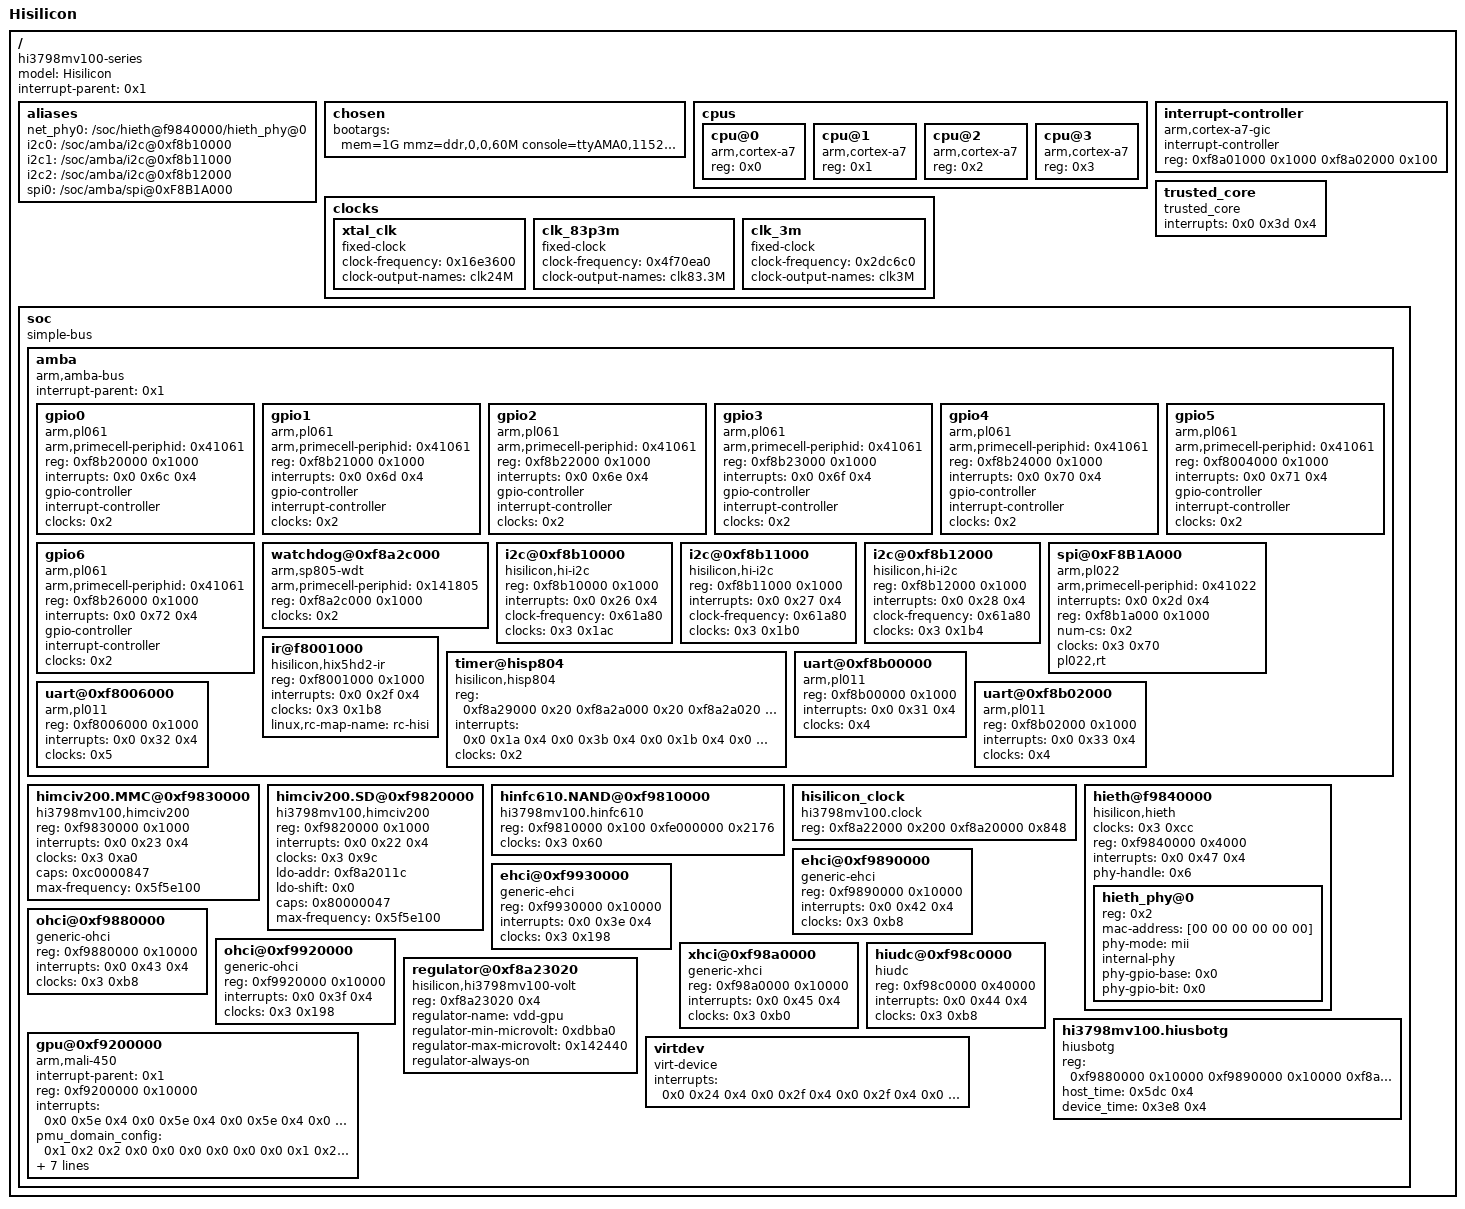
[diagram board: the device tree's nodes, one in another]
/dts-v1/;
// Decompiled from DTB appended to hi_kernel.bin at offset 0xA59D50
// DTB version: 17, size: 8935 bytes

/ {
	model = "Hisilicon";
	compatible = "hi3798mv100-series";
	#address-cells = <0x1>;
	#size-cells = <0x1>;
	interrupt-parent = <0x1>;
	aliases {
		net_phy0 = "/soc/hieth@f9840000/hieth_phy@0";
		i2c0 = "/soc/amba/i2c@0xf8b10000";
		i2c1 = "/soc/amba/i2c@0xf8b11000";
		i2c2 = "/soc/amba/i2c@0xf8b12000";
		spi0 = "/soc/amba/spi@0xF8B1A000";
	};
	chosen {
		bootargs = "mem=1G mmz=ddr,0,0,60M console=ttyAMA0,115200 root=/dev/mmcblk0p9 rootfstype=ext4 rootwait blkdevparts=mmcblk0:1M(boot),1M(bootargs),4M(baseparam),4M(pqparam),4M(logo),20M(kernel),64M(busybox),512M(backup),-(ubuntu)";
	};
	cpus {
		#address-cells = <0x1>;
		#size-cells = <0x0>;
		cpu@0 {
			device_type = "cpu";
			compatible = "arm,cortex-a7";
			reg = <0x0>;
		};
		cpu@1 {
			device_type = "cpu";
			compatible = "arm,cortex-a7";
			reg = <0x1>;
		};
		cpu@2 {
			device_type = "cpu";
			compatible = "arm,cortex-a7";
			reg = <0x2>;
		};
		cpu@3 {
			device_type = "cpu";
			compatible = "arm,cortex-a7";
			reg = <0x3>;
		};
	};
	clocks {
		xtal_clk {
			compatible = "fixed-clock";
			#clock-cells = <0x0>;
			clock-frequency = <0x16e3600>;
			clock-output-names = "clk24M";
			linux,phandle = <0x2>;
			phandle = <0x2>;
		};
		clk_83p3m {
			compatible = "fixed-clock";
			#clock-cells = <0x0>;
			clock-frequency = <0x4f70ea0>;
			clock-output-names = "clk83.3M";
			linux,phandle = <0x4>;
			phandle = <0x4>;
		};
		clk_3m {
			compatible = "fixed-clock";
			#clock-cells = <0x0>;
			clock-frequency = <0x2dc6c0>;
			clock-output-names = "clk3M";
			linux,phandle = <0x5>;
			phandle = <0x5>;
		};
	};
	interrupt-controller {
		compatible = "arm,cortex-a7-gic";
		#interrupt-cells = <0x3>;
		#address-cells = <0x0>;
		interrupt-controller;
		reg = <0xf8a01000 0x1000 0xf8a02000 0x100>;
		linux,phandle = <0x1>;
		phandle = <0x1>;
	};
	trusted_core {
		compatible = "trusted_core";
		interrupts = <0x0 0x3d 0x4>;
	};
	soc {
		#address-cells = <0x1>;
		#size-cells = <0x1>;
		compatible = "simple-bus";
		device_type = "soc";
		ranges = <0x0 0x0 0xffffffff>;
		amba {
			compatible = "arm,amba-bus";
			#address-cells = <0x1>;
			#size-cells = <0x1>;
			interrupt-parent = <0x1>;
			ranges;
			gpio0 {
				compatible = "arm,pl061", "arm,primecell";
				arm,primecell-periphid = <0x41061>;
				reg = <0xf8b20000 0x1000>;
				interrupts = <0x0 0x6c 0x4>;
				gpio-controller;
				#gpio-cells = <0x2>;
				interrupt-controller;
				#interrupt-cells = <0x2>;
				clocks = <0x2>;
				clock-names = "apb_pclk";
			};
			gpio1 {
				compatible = "arm,pl061", "arm,primecell";
				arm,primecell-periphid = <0x41061>;
				reg = <0xf8b21000 0x1000>;
				interrupts = <0x0 0x6d 0x4>;
				gpio-controller;
				#gpio-cells = <0x2>;
				interrupt-controller;
				#interrupt-cells = <0x2>;
				clocks = <0x2>;
				clock-names = "apb_pclk";
			};
			gpio2 {
				compatible = "arm,pl061", "arm,primecell";
				arm,primecell-periphid = <0x41061>;
				reg = <0xf8b22000 0x1000>;
				interrupts = <0x0 0x6e 0x4>;
				gpio-controller;
				#gpio-cells = <0x2>;
				interrupt-controller;
				#interrupt-cells = <0x2>;
				clocks = <0x2>;
				clock-names = "apb_pclk";
			};
			gpio3 {
				compatible = "arm,pl061", "arm,primecell";
				arm,primecell-periphid = <0x41061>;
				reg = <0xf8b23000 0x1000>;
				interrupts = <0x0 0x6f 0x4>;
				gpio-controller;
				#gpio-cells = <0x2>;
				interrupt-controller;
				#interrupt-cells = <0x2>;
				clocks = <0x2>;
				clock-names = "apb_pclk";
			};
			gpio4 {
				compatible = "arm,pl061", "arm,primecell";
				arm,primecell-periphid = <0x41061>;
				reg = <0xf8b24000 0x1000>;
				interrupts = <0x0 0x70 0x4>;
				gpio-controller;
				#gpio-cells = <0x2>;
				interrupt-controller;
				#interrupt-cells = <0x2>;
				clocks = <0x2>;
				clock-names = "apb_pclk";
			};
			gpio5 {
				compatible = "arm,pl061", "arm,primecell";
				arm,primecell-periphid = <0x41061>;
				reg = <0xf8004000 0x1000>;
				interrupts = <0x0 0x71 0x4>;
				gpio-controller;
				#gpio-cells = <0x2>;
				interrupt-controller;
				#interrupt-cells = <0x2>;
				clocks = <0x2>;
				clock-names = "apb_pclk";
			};
			gpio6 {
				compatible = "arm,pl061", "arm,primecell";
				arm,primecell-periphid = <0x41061>;
				reg = <0xf8b26000 0x1000>;
				interrupts = <0x0 0x72 0x4>;
				gpio-controller;
				#gpio-cells = <0x2>;
				interrupt-controller;
				#interrupt-cells = <0x2>;
				clocks = <0x2>;
				clock-names = "apb_pclk";
			};
			watchdog@0xf8a2c000 {
				compatible = "arm,sp805-wdt", "arm,primecell";
				arm,primecell-periphid = <0x141805>;
				reg = <0xf8a2c000 0x1000>;
				clocks = <0x2>;
				clock-names = "apb_pclk";
			};
			i2c@0xf8b10000 {
				compatible = "hisilicon,hi-i2c";
				reg = <0xf8b10000 0x1000>;
				interrupts = <0x0 0x26 0x4>;
				clock-frequency = <0x61a80>;
				clocks = <0x3 0x1ac>;
				clock-names = "apb_pclk";
				#address-cells = <0x1>;
				#size-cells = <0x0>;
			};
			i2c@0xf8b11000 {
				compatible = "hisilicon,hi-i2c";
				reg = <0xf8b11000 0x1000>;
				interrupts = <0x0 0x27 0x4>;
				clock-frequency = <0x61a80>;
				clocks = <0x3 0x1b0>;
				clock-names = "apb_pclk";
				#address-cells = <0x1>;
				#size-cells = <0x0>;
			};
			i2c@0xf8b12000 {
				compatible = "hisilicon,hi-i2c";
				reg = <0xf8b12000 0x1000>;
				interrupts = <0x0 0x28 0x4>;
				clock-frequency = <0x61a80>;
				clocks = <0x3 0x1b4>;
				clock-names = "apb_pclk";
				#address-cells = <0x1>;
				#size-cells = <0x0>;
			};
			spi@0xF8B1A000 {
				compatible = "arm,pl022", "arm,primecell";
				arm,primecell-periphid = <0x41022>;
				interrupts = <0x0 0x2d 0x4>;
				reg = <0xf8b1a000 0x1000>;
				num-cs = <0x2>;
				#address-cells = <0x1>;
				#size-cells = <0x0>;
				clocks = <0x3 0x70>;
				clock-names = "apb_pclk";
				pl022,rt;
			};
			ir@f8001000 {
				compatible = "hisilicon,hix5hd2-ir";
				reg = <0xf8001000 0x1000>;
				interrupts = <0x0 0x2f 0x4>;
				clocks = <0x3 0x1b8>;
				linux,rc-map-name = "rc-hisi";
			};
			timer@hisp804 {
				compatible = "hisilicon,hisp804";
				reg = <0xf8a29000 0x20 0xf8a2a000 0x20 0xf8a2a020 0x20 0xf8a2b000 0x20 0xf8a2b020 0x20>;
				interrupts = <0x0 0x1a 0x4 0x0 0x3b 0x4 0x0 0x1b 0x4 0x0 0x3c 0x4>;
				clocks = <0x2>;
				clock-names = "apb_pclk";
			};
			uart@0xf8b00000 {
				compatible = "arm,pl011", "arm,primecell";
				reg = <0xf8b00000 0x1000>;
				interrupts = <0x0 0x31 0x4>;
				clocks = <0x4>;
				clock-names = "apb_pclk";
			};
			uart@0xf8006000 {
				compatible = "arm,pl011", "arm,primecell";
				reg = <0xf8006000 0x1000>;
				interrupts = <0x0 0x32 0x4>;
				clocks = <0x5>;
				clock-names = "apb_pclk";
			};
			uart@0xf8b02000 {
				compatible = "arm,pl011", "arm,primecell";
				reg = <0xf8b02000 0x1000>;
				interrupts = <0x0 0x33 0x4>;
				clocks = <0x4>;
				clock-names = "apb_pclk";
			};
		};
		himciv200.MMC@0xf9830000 {
			compatible = "hi3798mv100,himciv200";
			reg = <0xf9830000 0x1000>;
			interrupts = <0x0 0x23 0x4>;
			clocks = <0x3 0xa0>;
			clock-names = "clk";
			caps = <0xc0000847>;
			max-frequency = <0x5f5e100>;
		};
		himciv200.SD@0xf9820000 {
			compatible = "hi3798mv100,himciv200";
			reg = <0xf9820000 0x1000>;
			interrupts = <0x0 0x22 0x4>;
			clocks = <0x3 0x9c>;
			clock-names = "clk";
			ldo-addr = <0xf8a2011c>;
			ldo-shift = <0x0>;
			caps = <0x80000047>;
			max-frequency = <0x5f5e100>;
		};
		hinfc610.NAND@0xf9810000 {
			compatible = "hi3798mv100.hinfc610";
			reg = <0xf9810000 0x100 0xfe000000 0x2176>;
			clocks = <0x3 0x60>;
			clock-names = "clk";
		};
		hisilicon_clock {
			compatible = "hi3798mv100.clock";
			reg = <0xf8a22000 0x200 0xf8a20000 0x848>;
			#clock-cells = <0x1>;
			linux,phandle = <0x3>;
			phandle = <0x3>;
		};
		hieth@f9840000 {
			compatible = "hisilicon,hieth";
			clocks = <0x3 0xcc>;
			clock-names = "clk";
			reg = <0xf9840000 0x4000>;
			interrupts = <0x0 0x47 0x4>;
			phy-handle = <0x6>;
			#address-cells = <0x1>;
			#size-cells = <0x0>;
			hieth_phy@0 {
				reg = <0x2>;
				mac-address = [00 00 00 00 00 00];
				phy-mode = "mii";
				internal-phy;
				phy-gpio-base = <0x0>;
				phy-gpio-bit = <0x0>;
				linux,phandle = <0x6>;
				phandle = <0x6>;
			};
		};
		ehci@0xf9890000 {
			compatible = "generic-ehci";
			reg = <0xf9890000 0x10000>;
			interrupts = <0x0 0x42 0x4>;
			clocks = <0x3 0xb8>;
			clock-names = "clk";
		};
		ehci@0xf9930000 {
			compatible = "generic-ehci";
			reg = <0xf9930000 0x10000>;
			interrupts = <0x0 0x3e 0x4>;
			clocks = <0x3 0x198>;
			clock-names = "clk";
		};
		ohci@0xf9880000 {
			compatible = "generic-ohci";
			reg = <0xf9880000 0x10000>;
			interrupts = <0x0 0x43 0x4>;
			clocks = <0x3 0xb8>;
			clock-names = "clk";
		};
		ohci@0xf9920000 {
			compatible = "generic-ohci";
			reg = <0xf9920000 0x10000>;
			interrupts = <0x0 0x3f 0x4>;
			clocks = <0x3 0x198>;
			clock-names = "clk";
		};
		xhci@0xf98a0000 {
			compatible = "generic-xhci";
			reg = <0xf98a0000 0x10000>;
			interrupts = <0x0 0x45 0x4>;
			clocks = <0x3 0xb0>;
			clock-names = "clk";
		};
		hiudc@0xf98c0000 {
			compatible = "hiudc";
			reg = <0xf98c0000 0x40000>;
			interrupts = <0x0 0x44 0x4>;
			clocks = <0x3 0xb8>;
			clock-names = "clk";
		};
		hi3798mv100.hiusbotg {
			compatible = "hiusbotg";
			reg = <0xf9880000 0x10000 0xf9890000 0x10000 0xf8a20120 0x4>;
			host_time = <0x5dc 0x4>;
			device_time = <0x3e8 0x4>;
		};
		regulator@0xf8a23020 {
			compatible = "hisilicon,hi3798mv100-volt";
			reg = <0xf8a23020 0x4>;
			reg-names = "base-address";
			regulator-name = "vdd-gpu";
			regulator-min-microvolt = <0xdbba0>;
			regulator-max-microvolt = <0x142440>;
			regulator-always-on;
			status = "okay";
			linux,phandle = <0x7>;
			phandle = <0x7>;
		};
		gpu@0xf9200000 {
			compatible = "arm,mali-450", "arm,mali-utgard";
			interrupt-parent = <0x1>;
			reg = <0xf9200000 0x10000>;
			interrupts = <0x0 0x5e 0x4 0x0 0x5e 0x4 0x0 0x5e 0x4 0x0 0x5e 0x4 0x0 0x5e 0x4 0x0 0x5e 0x4 0x0 0x5e 0x4 0x0 0x5e 0x4>;
			interrupt-names = "IRQGP", "IRQGPMMU", "IRQPP0", "IRQPPMMU0", "IRQPP1", "IRQPPMMU1", "IRQPMU", "IRQPP";
			pmu_domain_config = <0x1 0x2 0x2 0x0 0x0 0x0 0x0 0x0 0x0 0x1 0x2 0x0>;
			pmu_switch_delay = <0x1ff>;
			#cooling-cells = <0x2>;
			clocks = <0x3 0x124>;
			clock-names = "clk_mali";
			mali-supply = <0x7>;
			operating-points-tt = <0x8f0d180 0x0 0xbebc200 0x0 0xee6b280 0x0 0x11e1a300 0x0 0x14997000 0x0 0x17d78400 0x0 0x19bfcc00 0x0 0x1dcd6500 0x0>;
			cooling-min-state = <0x0>;
			cooling-max-state = <0x7>;
			status = "okay";
		};
		virtdev {
			compatible = "virt-device";
			interrupts = <0x0 0x24 0x4 0x0 0x2f 0x4 0x0 0x2f 0x4 0x0 0x30 0x4 0x0 0x30 0x4 0x0 0x4b 0x4 0x0 0x52 0x4 0x0 0x54 0x4 0x0 0x58 0x4 0x0 0x5a 0x4 0x0 0x5b 0x4 0x0 0x5d 0x4 0x0 0x5e 0x4 0x0 0x5f 0x4 0x0 0x60 0x4 0x0 0x61 0x4 0x0 0x65 0x4 0x0 0x66 0x4 0x0 0x68 0x4 0x0 0x69 0x4 0x0 0x6a 0x4 0x0 0x7e 0x4>;
			interrupt-names = "sci0", "ir_std", "ir_s2", "keyled_ct1642", "keyled_std", "multicipher", "dmx", "aiao", "hdmi", "vdp", "tde", "vpss0", "gpu", "vdec_vdh", "png", "jpeg", "venc", "jpge", "vdec_scd", "vdec_vdh_safe", "vdec_scd_safe", "cipher";
		};
	};
};
